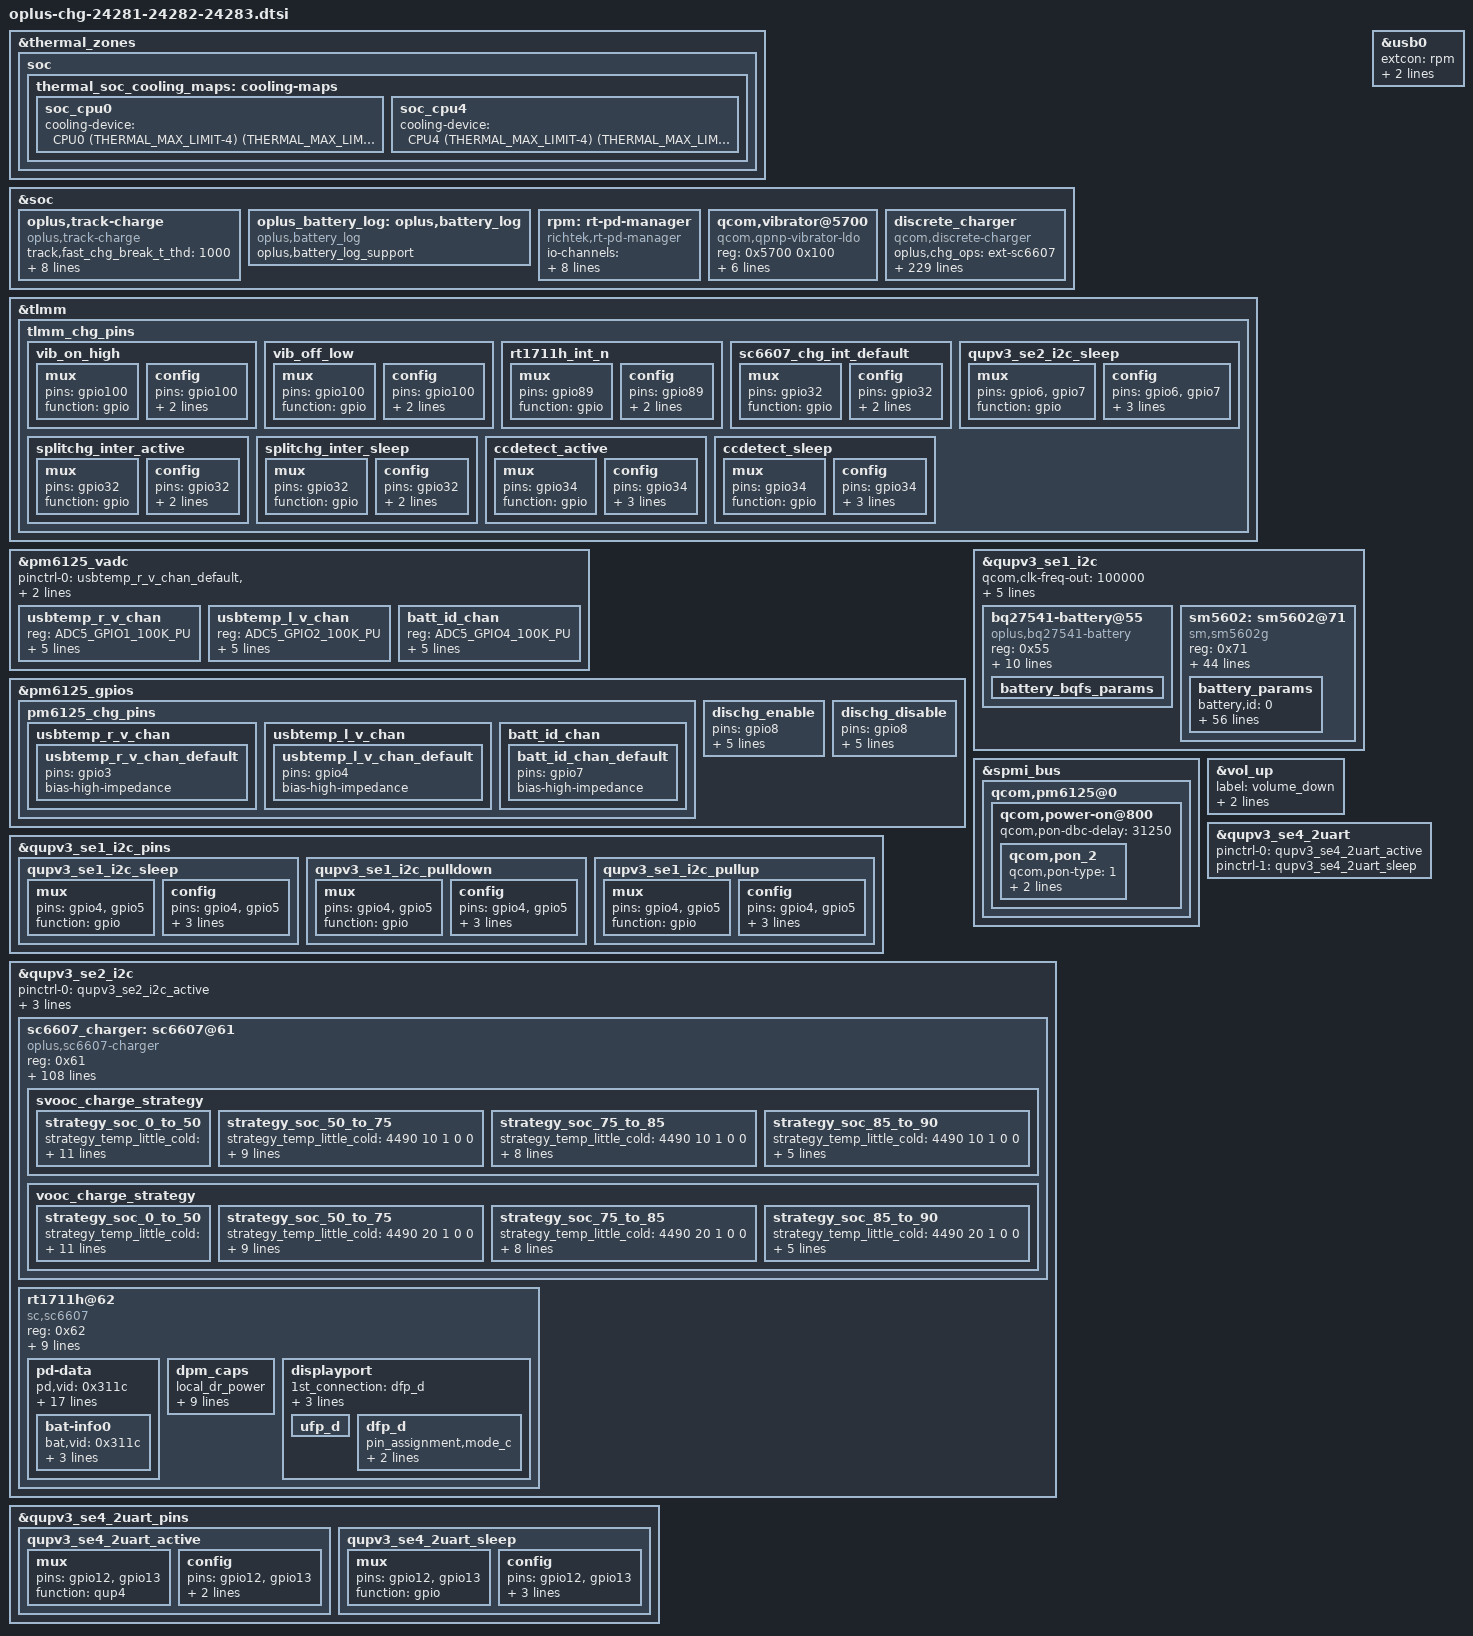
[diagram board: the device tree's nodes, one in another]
#include <dt-bindings/iio/qti_power_supply_iio.h>

&thermal_zones {
	soc {
		thermal_soc_cooling_maps: cooling-maps {
			soc_cpu0 {
				cooling-device =
					<&CPU0 (THERMAL_MAX_LIMIT-4)
						(THERMAL_MAX_LIMIT-4)>;
			};

			soc_cpu4 {
				cooling-device =
					<&CPU4 (THERMAL_MAX_LIMIT-4)
						(THERMAL_MAX_LIMIT-4)>;
			};

			/*soc_cpu6 {
				cooling-device = <&cpu6_isolate 1 1>;
			};

			soc_cpu7 {
				cooling-device = <&cpu7_isolate 1 1>;
			};*/
		};
	};
};

&soc {
	oplus,track-charge {
		compatible = "oplus,track-charge";
		track,fast_chg_break_t_thd = <1000>;
		track,general_chg_break_t_thd = <200>;
		track,voocphy_type = <2>;
		track,wired_max_power = <45000>;
		track,wired_fast_chg_scheme = <4>;
		track,gauge_status_ctrl;
		track,nominal_qmax1 = <5166>;
		track,nominal_fcc1 = <4700>;
		track,external_gauge_num = <1>;
	};

	oplus_battery_log: oplus,battery_log {
		compatible = "oplus,battery_log";
		oplus,battery_log_support;
	};
};

&tlmm {
	tlmm_chg_pins: tlmm_chg_pins {
		vib_on_high: vib_on_high {
			mux {
				pins = "gpio100";
				function = "gpio";
			};

			config {
				pins = "gpio100";
				drive-strength = <2>;
				output-high;
			};
		};
		vib_off_low: vib_off_low {
			mux {
				pins = "gpio100";
				function = "gpio";
			};

			config {
				pins = "gpio100";
				drive-strength = <2>;
				output-low;
			};
		};

		rt1711h_int_n: rt1711h_int_n {
			mux {
				pins = "gpio89";
				function = "gpio";
			};

			config {
				pins = "gpio89";
				drive-strength = <2>;
				bias-disable;
			};
		};

		sc6607_chg_int_default: sc6607_chg_int_default {
			mux {
				pins = "gpio32";
				function = "gpio";
			};

			config {
				pins = "gpio32";
				drive-strength = <2>;
				bias-disable;
			};
		};

		qupv3_se2_i2c_sleep: qupv3_se2_i2c_sleep {
				mux {
					pins = "gpio6", "gpio7";
					function = "gpio";
				};

				config {
					pins = "gpio6", "gpio7";
					drive-strength = <2>;
					bias-no-pull;
					output-high;
				};
		};

		/*split_chg*/
		splitchg_inter_active: splitchg_inter_active {
			mux {
				pins = "gpio32";
				function = "gpio";
			};
			config {
				pins = "gpio32";
				drive-strength = <2>;
				bias-pull-up;
			};
		};

		splitchg_inter_sleep: splitchg_inter_sleep {
			mux {
				pins = "gpio32";
				function = "gpio";
			};
			config {
				pins = "gpio32";
				drive-strength = <2>;
				bias-pull-up;
			};
		};

		ccdetect_active: ccdetect_active {
			mux {
				pins = "gpio34";
				function = "gpio";
			};
			config {
				pins = "gpio34";
				drive-strength = <2>;
				input-enable;
				//bias-pull-up; /*PULL UP*/
				bias-disable;
			};
		};

		ccdetect_sleep: ccdetect_sleep {
			mux {
				pins = "gpio34";
				function = "gpio";
			};
			config {
				pins = "gpio34";
				drive-strength = <2>;
				//output-low;
				//bias-pull-down; /*PULL DOWN*/
				input-enable;
				bias-disable;
			};
		};
	};
};

&pm6125_vadc {
	pinctrl-0 = <&usbtemp_r_v_chan_default &usbtemp_l_v_chan_default &batt_id_chan_default>;

	usbtemp_r_v_chan {
		reg = <ADC5_GPIO1_100K_PU>;
		label = "usbtemp_r_v_chan";
		qcom,ratiometric;
		qcom,hw-settle-time = <200>;
		qcom,pre-scaling = <1 1>;
		qcom,scale-fn-type = <ADC_SCALE_HW_CALIB_DEFAULT>;
	};

	usbtemp_l_v_chan {
		reg = <ADC5_GPIO2_100K_PU>;
		label = "usbtemp_l_v_chan";
		qcom,ratiometric;
		qcom,hw-settle-time = <200>;
		qcom,pre-scaling = <1 1>;
		qcom,scale-fn-type = <ADC_SCALE_HW_CALIB_DEFAULT>;
	};

	batt_id_chan {
		reg = <ADC5_GPIO4_100K_PU>;
		label = "batt_id_chan";
		qcom,ratiometric;
		qcom,hw-settle-time = <200>;
		qcom,pre-scaling = <1 1>;
		qcom,scale-fn-type = <ADC_SCALE_HW_CALIB_DEFAULT>;
	};
};

&pm6125_gpios {
	pm6125_chg_pins: pm6125_chg_pins {
			usbtemp_r_v_chan {
				usbtemp_r_v_chan_default: usbtemp_r_v_chan_default {
					pins = "gpio3";
					bias-high-impedance;
				};
			};

			usbtemp_l_v_chan {
				usbtemp_l_v_chan_default: usbtemp_l_v_chan_default {
					pins = "gpio4";
					bias-high-impedance;
				};
			};

			batt_id_chan {
				batt_id_chan_default: batt_id_chan_default {
					pins = "gpio7";
					bias-high-impedance;
				};
			};
	};
	dischg_enable: dischg_enable {
		pins = "gpio8";
		function = "normal";
		power-source = <0>;
		output-high;
		input-disable;
		qcom,drive-strength = <2>;
	};

	dischg_disable: dischg_disable {
		pins = "gpio8";
		function = "normal";
		power-source = <0>;
		output-low;
		input-disable;
		qcom,drive-strength = <2>;
	};
};

&qupv3_se1_i2c_pins {
	qupv3_se1_i2c_sleep: qupv3_se1_i2c_sleep {
		mux {
			pins = "gpio4", "gpio5";
			function = "gpio";
		};

		config {
			pins = "gpio4", "gpio5";
			drive-strength = <2>;
			bias-no-pull;
			output-high;
		};
	};
	qupv3_se1_i2c_pulldown: qupv3_se1_i2c_pulldown {
		mux {
			pins = "gpio4", "gpio5";
			function = "gpio";
		};

		config {
			pins = "gpio4", "gpio5";
			drive-strength = <2>;
			bias-pull-down;
			output-low;
		};
	};

	qupv3_se1_i2c_pullup: qupv3_se1_i2c_pullup {
		mux {
			pins = "gpio4", "gpio5";
			function = "gpio";
		};

		config {
			pins = "gpio4", "gpio5";
			drive-strength = <2>;
			bias-pull-up;
			input-enable;
		};
	};
};

&qupv3_se1_i2c {
	status = "okay";
	qcom,clk-freq-out = <100000>;
	pinctrl-names = "default", "sleep", "pulldown", "pullup";
	pinctrl-0 = <&qupv3_se1_i2c_active>;
	pinctrl-1 = <&qupv3_se1_i2c_sleep>;
	pinctrl-2 = <&qupv3_se1_i2c_pulldown>;
	pinctrl-3 = <&qupv3_se1_i2c_pullup>;
	oplus,i2c-auto-suspend-delay-ms = <3000>;
	bq27541-battery@55 {
		status = "okay";
		compatible = "oplus,bq27541-battery";
		reg = <0x55>;
		io-channels = <&pm6125_vadc ADC5_GPIO4_100K_PU>;
		io-channel-names = "batt_id_chan";
		dep-supply = <&pm6125_vadc>;
		oplus,gauge_abnormal_vbatt_max = <4800>;
		oplus,gauge_abnormal_vbatt_min = <2000>;
		oplus,cp_abnormal_fcc_max = <6600>;
		oplus,cp_abnormal_fcc_min = <3000>;
		oplus,cp_abnormal_soh_max = <100>;
		oplus,cp_abnormal_soh_min = <70>;
		oplus,cp_abnormal_qmax_max = <6600>;
		oplus,cp_abnormal_qmax_min = <4000>;
		battery_bqfs_params {
			#include "oplus-bqfs-24281.dtsi"
		};
	};

	sm5602:sm5602@71 {
		compatible = "sm,sm5602g";
		reg = <0x71>;

		sm,en_temp_ex;
		//sm,en_temp_in;
		//sm,en_temp_3rd;
		//sm,en_batt_det;
		sm,iocv_man_mode;
		sm,misc = <0x0800 0x0400>; //ex : 0x0800(Disabled DIS_HARD_RESET)
		sm,aging_ctrl = <0x0121>;
		sm,cycle_cfg = <0x7000>;
		sm,rsns = <5>;
		sm,battery_table_num = <0>;
		sm,param_version = <1>;
		sm,rpara = <0x0>;
		sm,curr_voffset = <0>;
		sm,curr_vslope = <0x8080>;

		//ENABLE_IOCV_ADJ
		sm,enable_iocv_adj;
		sm,iocv_max_adj_level = <0x1F33>;
		sm,iocv_min_adj_level = <0x1d70>;
		sm,ioci_max_adj_level = <0x1000>;
		sm,ioci_min_adj_level = <0xCC>;
		sm,iocv_i_slope = <100>;
		sm,iocv_i_offset = <0>;

		//ENABLE_INSPECTION_TABLE
		sm,enable_inspection_table;

		//ENABLE_TEMBASE_ZDSCON
		sm,enable_tembase_zdscon;
		sm,zdscon_act_temp_gap = <15>;
		sm,t_gap_denom = <5>;
		sm,hminman_t_value_fast = <125>;
		sm,i_gap_denom = <1000>;
		sm,hminman_i_value_fast = <150>;

		//ENABLE_TEMP_AVG
		sm,enable_temp_avg;
		sm,change_temp_time_limit = <1>;

		//ENABLE_NTC_COMPENSATION
		//sm,enable_ntc_compensation;
		sm,rtrace = <4700>;
		sm,overheat_th_deg = <50>;
		sm,cold_th_deg = <0>;

		//ENABLE_LTIM_ACT
		sm,enable_ltim_act;
		sm,ltim_act_temp_gap = <24>;
		sm,ltim_i_limit = <1500>;
		sm,ltim_factor = <42>;
		sm,ltim_denom = <130>;
		sm,ltim_min = <0xA>;

		//ENABLE_HCIC_ACT
		sm,enable_hcic_act;
		sm,hcic_min = <4000>;
		sm,hcic_factor = <2>;
		sm,hcic_denom = <200>;

		//ENABLE_HCRSM_MODE
		//sm,enable_hcrsm_mode;
		sm,hcrsm_volt = <4450>;
		sm,hcrsm_curr = <1750>;
		sm,hcrsm_min_soc = <900>;

		//CHECK_ABNORMAL_TABLE
		sm,enable_check_abnormal_table;

		battery_params {
			//1st NVT Battery( pack, liwon µçÐ¾
		    	battery,id = <0>;
			battery0,param_version = <1>;
		    	battery0,max_voltage_uv = <4500000>;
		        battery0,battery_type = <4500 0x0 0x2C20>;
		    	battery0,battery_table0 = <0x1400 0x1B33 0x1C3B 0x1D08 0x1D78 0x1D92 0x1DA1 0x1DEA 0x1E17 0x1E66 0x1E86 0x1EAF 0x1EE3 0x1F4F 0x1FDA 0x203F 0x20AC 0x2123 0x21A2 0x2230 0x2286 0x2320 0x2373 0x2666>;
		    	battery0,battery_table1 = <0x0 0x66 0x196 0x322 0x4AD 0x7C5 0xB60 0x1087 0x15AE 0x1D69 0x2290 0x27B7 0x2CDE 0x3498 0x39BF 0x3EE6 0x440E 0x4935 0x4E5C 0x5616 0x59B1 0x60E8 0x6400 0x64E6>;
			battery0,battery_table2 = <0x1A2B 0x1215 0x1011 0x0D0E 0x0C0C 0x0B0B 0x0B0B 0x0A0A>;
			battery0,alpha = <0x00CC>;
			battery0,beta = <0x0025>;
			battery0,rs = <0x8052>;
			battery0,rs_value = <0x0050 0x010A 0x3800 0x0048>;
			battery0,vit_period = <0x315A>;
			battery0,volt_cal = <0x8000>;
			battery0,mix_value = <0x0003>;
			battery0,curr_offset = <0x0000>;
			battery0,curr_slope = <0x8080>;
			battery0,topoff_soc = <7 450 150>;
			battery0,temp_std = <25>;
			battery0,temp_offset = <0 11 1 0 8 (-1)>;
			battery0,temp_cal = <0 6 1 11 (-1) 0 6 1 9 1>;
			battery0,ext_temp_cal = <0 2 1 2 1 1 2 3 2 3>;
			battery0,static_scale_soc = <0 991 1000 (-50) 50 1>;
			battery0,tem_poff = <3400 100>;
			battery0,thermal_table = <0x6177 0x60E6 0x604E 0x5FAF 0x5F06 0x5E56 0x5DA3 0x5CEC 0x5C27 0x5B5A
					 0x5A88 0x59AD 0x58C6 0x57D8 0x56E5 0x55E8 0x54E5 0x53CF 0x52B5 0x519B
					 0x506E 0x4F35 0x4E07 0x4CC0 0x4B76 0x4A25 0x48BD 0x475D 0x45F5 0x4477
					 0x4304 0x4175 0x3FDE 0x3E4A 0x3CA2 0x3AF6 0x3945 0x378A 0x35CB 0x33FC
					 0x322B 0x3059 0x2E82 0x2CA0 0x2AC6 0x28C6 0x26E0 0x24EA 0x22E8 0x20EF
					 0x1EE7 0x1CEE 0x1AE8 0x18D0 0x16D6 0x14CE 0x12F3 0x10E4 0x0ED6 0x0CC4
					 0x0ABC 0x08BC 0x06A8 0x04AD 0x02A1 0x009E 0xF669 0xF471 0xF278 0xF081
					 0xEE7B 0xEC8C 0xEAA1 0xE8BE 0xE6E1 0xE505 0xE332 0xE162 0xDF9B 0xDDD9
					 0xDC1F 0xDA67 0xD8B4 0xD70B 0xD565 0xD3C7 0xD232 0xD0A1 0xCF18 0xCD94
					 0xCC18 0xCAA5 0xC936 0xC7D3 0xC670 0xC519 0xC3C6 0xC27A 0xC136 0xBFF7
					 0xBEC1 0xBD92 0xBC6E 0xBB4D 0xBA36 0xB922 0xB816 0xB712 0xB611 0xB517
					 0xB422 0xB334 0xB249 0xB164 0xB085 0xAFAD 0xAED8 0xAE0A 0xAD3E 0xAC78
					 0xABB7 0xAAFD 0xAA48 0xA997 0xA8E8 0xA841>;  //NTC value(DEC) table -40~85 20K PU,20K PD/10K NTC
			//2nd SWD Battery(pack, ATL µçÐ¾
	    		//battery,id = <1>;
			battery1,param_version = <1>;
		    	battery1,max_voltage_uv = <4500000>;
		        battery1,battery_type = <4500 0x0 0x2CA8>;
		    	battery1,battery_table0 = <0x1400 0x1B32 0x1C51 0x1D12 0x1D78 0x1D93 0x1DB5 0x1DF5 0x1E20 0x1E68 0x1E86 0x1EB0 0x1EE5 0x1F55 0x1FDD 0x203F 0x20AB 0x2122 0x21A1 0x222B 0x2281 0x231D 0x2370 0x2666>;
		    	battery1,battery_table1 = <0x0 0x66 0x1BC 0x343 0x4CA 0x8DD 0xC6E 0x1185 0x169C 0x1E3F 0x2357 0x286E 0x2D85 0x3529 0x3A40 0x3F57 0x446F 0x4986 0x4E9D 0x5640 0x59D1 0x60F1 0x6400 0x64E6>;
			battery1,battery_table2 = <0x1B2D 0x1517 0x1213 0x0F10 0x0E0F 0x0D0E 0x0C0D 0x0C0C>;
			battery1,alpha = <0x00CC>;
			battery1,beta = <0x0025>;
			battery1,rs = <0x8052>;
			battery1,rs_value = <0x0050 0x010A 0x3800 0x0048>;
			battery1,vit_period = <0x315A>;
			battery1,volt_cal = <0x8000>;
			battery1,mix_value = <0x0003>;
			battery1,curr_offset = <0x0000>;
			battery1,curr_slope = <0x8080>;
			battery1,topoff_soc = <7 450 150>;
			battery1,temp_std = <25>;
			battery1,temp_offset = <0 11 1 0 8 (-1)>;
			battery1,temp_cal = <0 6 1 11 (-1) 0 6 1 9 1>;
			battery1,ext_temp_cal = <0 2 1 2 1 1 2 3 2 3>;
			battery1,static_scale_soc = <0 991 1000 (-50) 50 1>;
			battery1,tem_poff = <3400 100>;
			battery1,thermal_table = <0x506E 0x4F35 0x4E07 0x4CC0 0x4B76 0x4A25 0x48BD 0x475D 0x45F5 0x4477
						0x4304 0x4175 0x3FDE 0x3E4A 0x3CA2 0x3AF6 0x3945 0x378A 0x35CB 0x33FC
						0x322B 0x3059 0x2E82 0x2CA0 0x2AC6 0x28C6 0x26E0 0x24EA 0x22E8 0x20EF
						0x1EE7 0x1CEE 0x1AE8 0x18D0 0x16D6 0x14CE 0x12F3 0x10E4 0x0ED6 0x0CC4
						0x0ABC 0x08BC 0x06A8 0x04AD 0x02A1 0x009E 0xF669 0xF471 0xF278 0xF081
						0xEE7B 0xEC8C 0xEAA1 0xE8BE 0xE6E1 0xE505 0xE332 0xE162 0xDF9B 0xDDD9
						0xDC1F 0xDA67 0xD8B4 0xD70B 0xD565 0xD3C7 0xD232 0xD0A1 0xCF18 0xCD94
						0xCC18 0xCAA5 0xC936 0xC7D3 0xC670 0xC519 0xC3C6 0xC27A 0xC136 0xBFF7
						0xBEC1 0xBD92 0xBC6E 0xBB4D 0xBA36 0xB922 0xB816 0xB712 0xB611 0xB517
						0xB422 0xB334 0xB249 0xB164 0xB085 0xAFAD 0xAED8 0xAE0A 0xAD3E 0xAC78
						0xABB7>;  //NTC value(DEC) table -20~80 20K PU,20K PD/10K NTC
		};
	};
};


&soc {
	rpm: rt-pd-manager {
		compatible = "richtek,rt-pd-manager";
		#io-channel-cells = <1>;
		io-channels = <&discrete_charger PSY_IIO_PD_ACTIVE>,
			      <&discrete_charger PSY_IIO_PD_USB_SUSPEND_SUPPORTED>,
			      <&discrete_charger PSY_IIO_PD_IN_HARD_RESET>,
			      <&discrete_charger PSY_IIO_PD_CURRENT_MAX>,
			      <&discrete_charger PSY_IIO_PD_VOLTAGE_MIN>,
			      <&discrete_charger PSY_IIO_PD_VOLTAGE_MAX>,
			      <&discrete_charger PSY_IIO_USB_REAL_TYPE>,
			      <&discrete_charger PSY_IIO_PD_SDP>;
		io-channel-names = "pd_active",
				   "pd_usb_suspend_supported",
				   "pd_in_hard_reset",
				   "pd_current_max",
				   "pd_voltage_min",
				   "pd_voltage_max",
				   "real_type",
				   "pd_sdp";
	};
};
/* load vibrator for rm pmic */
&soc {
	qcom,vibrator@5700 {
			compatible = "qcom,qpnp-vibrator-ldo";
			reg = <0x5700 0x100>;
			qcom,vib-ldo-volt-uv = <3000000>;
			qcom,disable-overdrive;
			qcom,vib-type = <1>;	/* 0:ldo 1:gpio */
			status = "okay";

			qcom,vibrator_switch-gpio = <&tlmm 100 0x00>;
			pinctrl-names = "vib_on_high", "vib_off_low";
			pinctrl-0 = <&vib_on_high>;
			pinctrl-1 = <&vib_off_low >;
	};
};

&spmi_bus {
	qcom,pm6125@0 {
		qcom,power-on@800 {
			qcom,pon-dbc-delay = <31250>;
		};
	};
};

&vol_up {
	label = "volume_down";
	linux,code = <KEY_VOLUMEDOWN>;
	debounce-interval = <32>;
};

&qupv3_se2_i2c {
	status = "okay";
	pinctrl-0 = <&qupv3_se2_i2c_active>;
	pinctrl-1 = <&qupv3_se2_i2c_sleep>;
	qcom,clk-freq-out = <400000>;
	oplus,i2c-auto-suspend-delay-ms = <3000>;
	sc6607_charger:sc6607@61 {
		status = "okay";
		compatible = "oplus,sc6607-charger";
		reg = <0x61>; /*The device operates as a slave device with address 75H*/

		qcom,chg_irq_gpio = <&tlmm 32 0x00>;
		dpdm-supply = <&qusb_phy0>;
		pinctrl-names = "default",
				"splitchg_inter_active",
				"splitchg_inter_sleep";

		pinctrl-0 = <&sc6607_chg_int_default>;
		pinctrl-1 = <&splitchg_inter_active>;
		pinctrl-2 = <&splitchg_inter_sleep>;

		sc,vsys-limit = <3400>;
		sc,vbat = <4450>;
		sc,charge-curr = <2000>;
		sc,iindpm-disable = <0>;
		sc,input-curr-limit = <500>;
		sc,ico-enable = <0>;
		sc,precharge-volt = <0>;      /* 0:2700mv , 1:3000mv */
		sc,precharge-curr = <500>;
		sc,term-en = <1>;
		sc,term-curr = <100>;     /* ma */
		sc,rechg-dis = <1>;
		sc,boost-voltage = <5000>;
		sc,boost-max-current = <1500>;
		sc,support-tsbat-1000k;
		sc,conv-ocp-dis = <0>;
		sc,tsbat-jeita-dis = <1>;
		sc,vpmid-ovp-otg-dis = <0>;
		sc,vbat-ovp-buck-dis = <0>;
		sc,ibat-ocp = <1>;    /* 0:10A , 1:16A */
		ovp_reg = <0x36>; /* 4850mv */
		ocp_reg = <0xf>;    /* 4.75A*/
		pmid2out_ovp_thr = <0x07>; /* 600mV */
		sc,charge-detect-enable;
		sc,disable-qc;
		sc,cc_pull_up_idrive = <0x09>;
		sc,cc_pull_down_idrive = <0x43>;
		sc,continuous_time = <0x4E>;
		sc,bmc_width = <0x86 0x3d 0x3b 0x10>;
		qcom,copycat_vooc_support;
		oplus,copycat_identify_algorithm = <2>;
		oplus,copycat-vooc-count = <4>;

		/*
		 * Charger name
		 * Main charger: primary_chg
		 * Slave charger: secondary_chg
		 */
		charger_name = "primary_chg";


		qcom,voocphy_current_default = <41>;/*4100mA*/

		qcom,svooc_cool_down_current_limit = <82 20 20 24 30 34 40 44 50 54 82>;
		qcom,vooc_cool_down_current_limit = <30 20 20 24 30>;
		qcom,abnormal_adapter_current = <60 60 40 40>;
		oplus,workaround_for_100w;
		qcom,vooc_little_cold_full_voltage = <4490>;
		qcom,vooc_cool_full_voltage = <4500>;
		qcom,vooc_warm_full_voltage = <4130>;
		qcom,vooc_1time_full_voltage = <4560>;
		qcom,vooc_ntime_full_voltage = <4550>;
		qcom,low_curr_full_t1 = <120>;
		qcom,low_curr_full_t2 = <350>;
		qcom,low_curr_full_t3 = <430>;
		qcom,range1_low_curr_full = <1350 4550
					     1300 4545
					     1200 4530
					     1100 4520
					     950 4510>;
		qcom,range2_low_curr_full = <1950 4550
					     1900 4545
					     1800 4530
					     1700 4520
					     1550 4510>;

		qcom,vooc_multistep_initial_batt_temp = <1000>;
		qcom,vooc_little_cool_temp = <200>;
		qcom,vooc_cool_temp = <120>;
		qcom,vooc_little_cold_temp = <50>;
		qcom,vooc_normal_low_temp = <350>;
		qcom,vooc_strategy_normal_current = <100>;
		qcom,vooc_normal_to_little_cool_current = <100>;
		qcom,vooc_batt_over_high_temp = <510>;
		qcom,vooc-low-temp = <0>;
		qcom,vooc-high-temp = <500>;
		qcom,vooc-low-soc = <0>;
		qcom,vooc-high-soc = <90>;
		qcom,vooc-normal-high-temp = <440>;
		qcom,vooc-warm-allow-vol = <4000>;
		qcom,vooc-warm-allow-soc = <50>;
		qcom,impedance_calculation_newmethod;
		qcom,svooc_circuit_r_l = <0x18>;
		qcom,svooc_circuit_r_h = <0x2>;/* 65 mR */

		qcom,vooc_strategy1_batt_high_temp0 = <385>;
		qcom,vooc_strategy1_batt_high_temp1 = <395>;
		qcom,vooc_strategy1_batt_high_temp2 = <420>;
		qcom,vooc_strategy1_batt_low_temp2 = <410>;
		qcom,vooc_strategy1_batt_low_temp1 = <385>;
		qcom,vooc_strategy1_batt_low_temp0 = <375>;

		qcom,vooc_strategy1_high_current0 = <82>;
		qcom,vooc_strategy1_high_current1 = <60>;
		qcom,vooc_strategy1_high_current2 = <40>;
		qcom,vooc_strategy1_low_current2 = <60>;
		qcom,vooc_strategy1_low_current1 = <60>;
		qcom,vooc_strategy1_low_current0 = <82>;

		qcom,vooc_strategy1_high_current0_vooc = <30>;
		qcom,vooc_strategy1_high_current1_vooc = <30>;
		qcom,vooc_strategy1_high_current2_vooc = <30>;
		qcom,vooc_strategy1_low_current2_vooc = <30>;
		qcom,vooc_strategy1_low_current1_vooc = <30>;
		qcom,vooc_strategy1_low_current0_vooc = <30>;

		qcom,voocphy_ibat_over_current = <8500>;
		qcom,voocphy_cp_max_ibus = <4750>;
		qcom,voocphy_svooc_cp_max_ibus = <4750>;
		qcom,voocphy_vooc_cp_max_ibus = <3500>;
		qcom,batt_pwd_curr_thd1 = <4300>;
		qcom,batt_pwd_vol_thd1 = <4514>;

		qcom,voocphy_freq_mincore = <1017600>;
		qcom,voocphy_freq_midcore = <1804800>;
		qcom,voocphy_freq_maxcore = <1804800>;
		qcom,voocphy_current_change_timeout = <100>;
		oplus,sc6607_ntc_surport_1000k = <
			(-40) 4251000 (-39) 3962000 (-38) 3695000 (-37) 3447000 (-36) 3218000 (-35) 3005000
			(-34) 2807000 (-33) 2624000 (-32) 2454000 (-31) 2296000 (-30) 2149000 (-29) 2012000
			(-28) 1885000 (-27) 1767000 (-26) 1656000 (-25) 1554000 (-24) 1458000 (-23) 1369000
			(-22) 1286000 (-21) 1208000 (-20) 1135000 (-19) 1068000 (-18) 1004000 (-17) 945000
			(-16) 889600 (-15) 837800 (-14) 789300 (-13) 743900 (-12) 701300 (-11) 661500
			(-10) 624100 (-9) 589000 (-8) 556200 (-7) 525300 (-6) 496300 (-5) 469100
			(-4) 443500 (-3) 419500 (-2) 396900 (-1) 375600 0 355600 1 336800
			2 319100 3 302400 4 286700 5 271800 6 257800 7 244700
			8 232200 9 220500 10 209400 11 198900 12 189000 13 179700
			14 170900 15 162500 16 154600 17 147200 18 140100 19 133400
			20 127000 21 121000 22 115400 23 110000 24 104800 25 100000
			26 95400 27 91040 28 86900 29 82970 30 79230 31 75690
			32 72320 33 69120 34 66070 35 63180 36 60420 37 57810
			38 55310 39 52940 40 50680 41 48530 42 46490 43 44530
			44 42670 45 40900 46 39210 47 37600 48 36060 49 34600
			50 33190 51 31860 52 30580 53 29360 54 28200 55 27090
			56 26030 57 25010 58 24040 59 23110 60 22220 61 21370
			62 20560 63 19780 64 19040 65 18320 66 17640 67 16990
			68 16360 69 15760 70 15180 71 14630 72 14100 73 13600
			74 13110 75 12640 76 12190 77 11760 78 11350 79 10960
			80 10580 81 10210 82 9859 83 9522 84 9198 85 8887
			86 8587 87 8299 88 8022 89 7756 90 7500 91 7254
			92 7016 93 6788 94 6568 95 6357 96 6153 97 5957
			98 5768 99 5586 100 5410 101 5241 102 5078 103 4921
			104 4769 105 4623 106 4482 107 4346 108 4215 109 4088
			110 3966 111 3848 112 3734 113 3624 114 3518 115 3415
			116 3316 117 3220 118 3128 119 3038 120 2952 121 2868
			122 2787 123 2709 124 2634 125 2561>;

		svooc_batt_sys_curve = <0 1 0 1 0 0 1	// 4100mA
					0 0 0 0 0 0 1	// 3414mV
					0 0 1 0 1 0 0	// 2000mA
					1 1 1 1 1 1 0	// 4664mV
					0 0 0 1 0 1 0	// 1000mA
					1 1 1 1 1 1 0>;	// 4664mV

		vooc_batt_sys_curve =  <0 0 1 1 1 1 0	// 3000mA
					0 0 0 0 0 0 1	// 3414mV
					0 0 1 0 1 0 0	// 2000mA
					1 1 1 1 1 1 0	// 4664mV
					0 0 0 1 0 1 0	// 1000mA
					1 1 1 1 1 1 0>;	// 4664mV

	    svooc_charge_strategy {
			strategy_soc_0_to_50 {
				strategy_temp_little_cold =	<4150 19 0 0 0
								 4150 15 0 0 0
								 4480 13 0 0 0
								 4490 10 1 0 0>;
				strategy_temp_cool =		<4150 28 0 0 0
								 4150 25 0 0 0
								 4150 20 0 0 0
								 4490 19 0 0 0
								 4490 15 0 0 0
								 4500 10 1 0 0>;
				strategy_temp_little_cool = 	<4150 41 0 0 0
								 4150 40 0 0 0
								 4150 35 0 0 0
								 4510 33 0 0 0
								 4510 30 0 0 0
								 4510 25 0 0 0
								 4540 22 0 0 0
								 4540 20 0 0 0
								 4540 15 0 0 0
								 4550 10 1 0 0>;
				strategy_temp_normal_low = 	<4230 41 0 0 0
								 4230 40 0 0 0
								 4230 35 0 0 0
								 4510 33 0 0 0
								 4510 30 0 0 0
								 4510 25 0 0 0
								 4540 22 0 0 0
								 4540 20 0 0 0
								 4540 15 0 0 0
								 4550 10 1 0 0>;
				strategy_temp_normal_high =	<4230 41 0 0 0
								 4230 40 0 0 0
								 4230 35 0 0 0
								 4510 33 0 0 0
								 4510 30 0 0 0
								 4510 25 0 0 0
								 4540 22 0 0 0
								 4540 20 0 0 0
								 4540 15 0 0 0
								 4550 10 1 0 0>;
				strategy_temp_warm =		<4120 15 0 0 0
								 4130 10 1 0 0>;
			};

			strategy_soc_50_to_75 {
				strategy_temp_little_cold =	<4490 10 1 0 0>;
				strategy_temp_cool =		<4490 15 0 0 0
								 4500 10 1 0 0>;
				strategy_temp_little_cool = 	<4540 20 0 0 0
								 4540 15 0 0 0
								 4550 10 1 0 0>;
				strategy_temp_normal_low = 	<4510 25 0 0 0
								 4540 22 0 0 0
								 4540 20 0 0 0
								 4540 15 0 0 0
								 4550 10 1 0 0>;
				strategy_temp_normal_high =	<4510 25 0 0 0
								 4540 22 0 0 0
								 4540 20 0 0 0
								 4540 15 0 0 0
								 4550 10 1 0 0>;
				strategy_temp_warm =		<4130 10 1 0 0>;//no fastcharge
			};

			strategy_soc_75_to_85 {
				strategy_temp_little_cold = 	<4490 10 1 0 0>;
				strategy_temp_cool =		<4500 10 1 0 0>;
				strategy_temp_little_cool =	<4540 15 0 0 0
								 4550 10 1 0 0>;
				strategy_temp_normal_low =	<4540 15 0 0 0
								 4550 10 1 0 0>;
				strategy_temp_normal_high =	<4540 15 0 0 0
								 4550 10 1 0 0>;
				strategy_temp_warm =		<4130 10 1 0 0>;//no fastcharge
			};

			strategy_soc_85_to_90 {
				strategy_temp_little_cold = 	<4490 10 1 0 0>;
				strategy_temp_cool =		<4500 10 1 0 0>;
				strategy_temp_little_cool =	<4550 10 1 0 0>;
				strategy_temp_normal_low =	<4550 10 1 0 0>;
				strategy_temp_normal_high =	<4550 10 1 0 0>;
				strategy_temp_warm =		<4130 10 1 0 0>;//no fastcharge
			};
		};

		vooc_charge_strategy {
			strategy_soc_0_to_50 {
				strategy_temp_little_cold =	<4150 30 0 0 0
								 4480 26 0 0 0
								 4490 20 1 0 0>;
				strategy_temp_cool =		<4490 30 0 0 0
								 4500 20 1 0 0>;
				strategy_temp_little_cool =	<4540 30 0 0 0
								 4550 20 1 0 0>;
				strategy_temp_normal_low =	<4540 30 0 0 0
								 4550 20 1 0 0>;
				strategy_temp_normal_high =	<4540 30 0 0 0
								 4550 20 1 0 0>;
				strategy_temp_warm =		<4120 30 0 0 0
								 4130 20 1 0 0>;
			};

			strategy_soc_50_to_75 {
				strategy_temp_little_cold =	<4490 20 1 0 0>;
				strategy_temp_cool =		<4490 30 0 0 0
								 4500 20 1 0 0>;
				strategy_temp_little_cool =	<4540 30 0 0 0
								 4550 20 1 0 0>;
				strategy_temp_normal_low =	<4540 30 0 0 0
								 4550 20 1 0 0>;
				strategy_temp_normal_high =	<4540 30 0 0 0
								 4550 20 1 0 0>;
				strategy_temp_warm =		<4130 20 1 0 0>;
			};

			strategy_soc_75_to_85 {
				strategy_temp_little_cold =	<4490 20 1 0 0>;
				strategy_temp_cool =		<4500 20 1 0 0>;
				strategy_temp_little_cool =	<4540 30 0 0 0
								 4550 20 1 0 0>;
				strategy_temp_normal_low =	<4540 30 0 0 0
								 4550 20 1 0 0>;
				strategy_temp_normal_high =	<4540 30 0 0 0
								 4550 20 1 0 0>;
				strategy_temp_warm =		<4130 20 1 0 0>;
			};

			strategy_soc_85_to_90 {
				strategy_temp_little_cold =	<4490 20 1 0 0>;
				strategy_temp_cool =		<4500 20 1 0 0>;
				strategy_temp_little_cool =	<4550 20 1 0 0>;
				strategy_temp_normal_low =	<4550 20 1 0 0>;
				strategy_temp_normal_high =	<4550 20 1 0 0>;
				strategy_temp_warm =		<4130 20 1 0 0>;
			};
		};
	};


	rt1711h@62 {
		compatible = "sc,sc6607";
		reg = <0x62>;
		status = "okay";
		tcpc-dual,supported_modes = <0>; /* 0: dfp/ufp, */
						 /* 1: dfp, 2: ufp */
		rt-tcpc,name = "type_c_port0"; /* tcpc_device's name */
		rt-tcpc,role_def = <1>; /* 0: Unknown, 1: SNK, 2: SRC */
					/* 3: DRP, 4: Try.SRC, 5: Try.SNK */
		rt-tcpc,rp_level = <0>; /* 0: Default, 1: 1.5, 2: 3.0 */
		rt-tcpc,vconn_supply  = <1>;  /* 0: Never, 1: Always, */
					      /* 2: EMarkOnly, 3: StartOnly */
		/* rt-tcpc,disable_pe; */
		rt1711pd,intr_gpio = <&tlmm 89 0x0>;
		rt1711pd,intr_gpio_num = <89>;
		rt,disable_irq_reset;
		pinctrl-names = "default";
		pinctrl-0 = <&rt1711h_int_n>;
		pd-data {
			pd,vid = <0x311c>;
			pd,pid = <0x6600>;
			pd,source-cap-ext = /bits/ 8 <0x1c 0x31 0x00 0x66
						      0x00 0x00 0x00 0x00
						      0x00 0x00 0x00 0x00
						      0x00 0x00 0x00 0x00
						      0x00 0x00 0x00 0x00
						      0x00 0x00 0x01 0x05
						      0x00>;
			pd,sink-cap-ext = /bits/ 8 <0x1c 0x31 0x00 0x66
							   0x00 0x00 0x00 0x00
							   0x01 0x00 0x00 0x00
							   0x00 0x00 0x00 0x00
							   0x01 0x00 0x00 0x00
							   0x00 0x00 0x00 0x00>;
			pd,mfrs = "RichtekTCPC";

			/*
			 *	VSAFE5V = 0, MAX_POWER = 1, CUSTOM = 2,
			 *	MAX_POWER_LV = 0x21, MAX_POWER_LVIC = 0x31
			 *	MAX_POWER_HV = 0x41, MAX_POWER_HVIC = 0x51
			 */
			pd,charging_policy= <0>;

			/*
			 * Fixed 5V, 500 mA <0x00019032>
			 * Fixed 5V, 1A <0x00019064>
			 * Fixed 5V, 2A <0x000190c8>
			 * Fixed 5V, 3A <0x0001912c>
			 * Fixed 9V, 500 mA <0x0002d032>
			 * Fixed 9V, 1A <0x0002d064>
			 * Fixed 9V, 2A <0x0002d0c8>
			 * Fixed 9V, 3A <0x0002d12c>
			 * Variable 5-9V, 1A <0x8642d064>
			 * Variable 5-9V, 2A <0x8642d0c8>
			 * Variable 5-9V, 3A <0x8642d12c>
			 */
			pd,source-pdo-size = <1>;
			pd,source-pdo-data = <0x00019064>;
			pd,sink-pdo-size = <3>;
			pd,sink-pdo-data = <0x360190c8 0x0002d096 0xc0dc3252>;

			/*
			 * No DP, host + device
			 *	pd,id-vdo-size = <6>;
			 *	pd,id-vdo-data = <0xd14029cf 0x0 0x17110000
						  0x41800000 0x0 0x21800000>;
			 * With DP
			 *	pd,id-vdo-size = <6>;
			 *	pd,id-vdo-data = <0xd54029cf 0x0 0x17110000
						  0x41800000 0x0 0x21800000>;
			 */

			pd,id-vdo-size = <6>;
			pd,id-vdo-data = <0xd14029cf 0x0 0x17110000
					  0x41800000 0x0 0x21800000>;

			bat,nr = <1>;
			pd,country_nr = <0>;

			bat-info0 {
				bat,vid = <0x311c>;
				bat,pid = <0x6600>;
				bat,mfrs = "bat1";
				bat,design_cap = <17>;
			};

		};
		dpm_caps {
			local_dr_power;
			local_dr_data;
			//local_ext_power;
			local_usb_comm;
			//local_usb_suspend;
			//local_high_cap;
			//local_give_back;
			local_no_suspend;
			local_vconn_supply;

			//attempt_discover_cable_dfp;
			//attempt_enter_dp_mode;
			attempt_discover_cable;
			attempt_discover_id;
			attempt_discover_svid;

			/* 0: disable, 1: prefer_snk, 2: prefer_src */
			pr_check = <0>;
			//pr_reject_as_source;
			//pr_reject_as_sink;
			//pr_check_gp_source;
			//pr_check_gp_sink;

			/* 0: disable, 1: prefer_ufp, 2: prefer_dfp */
			dr_check = <0>;
			//dr_reject_as_dfp;
			//dr_reject_as_ufp;
		};
		displayport {
			/* connection type = "both", "ufp_d", "dfp_d" */
			1st_connection = "dfp_d";
			2nd_connection = "dfp_d";
			signal,dp_v13;
			//signal,dp_gen2;
			//usbr20_not_used;
			typec,receptacle;
			ufp_d {
				//pin_assignment,mode_a;
				//pin_assignment,mode_b;
				//pin_assignment,mode_c;
				//pin_assignment,mode_d;
				//pin_assignment,mode_e;
			};
			dfp_d {
				//pin_assignment,mode_a;
				//pin_assignment,mode_b;
				pin_assignment,mode_c;
				pin_assignment,mode_d;
				pin_assignment,mode_e;
				//pin_assignment,mode_f;
			};
		};
	};
};

&spmi_bus {
	qcom,pm6125@0 {
		qcom,power-on@800 {
			qcom,pon_2 {
				qcom,pon-type = <1>;
				qcom,pull-up = <1>;
				linux,code = <KEY_VOLUMEUP>;
			};
		};
	};
};

&soc {
	discrete_charger: discrete_charger {
		compatible = "qcom,discrete-charger";
		status = "okay";

		oplus,chg_ops = "ext-sc6607";
		#io-channel-cells = <1>;
		io-channels = <&pm6125_vadc ADC5_GPIO1_100K_PU>,
				      <&pm6125_vadc ADC5_GPIO2_100K_PU>;
		io-channel-names = "usbtemp_r_v_chan",
				"usbtemp_l_v_chan";
		dep-supply = <&pm6125_vadc>;
        //ntc switch gpio
        qcom,ntc-switch-gpio = <&tlmm 85 0x00>;

		pinctrl-names = "dischg_enable", "dischg_disable", "ccdetect_active", "ccdetect_sleep";

		pinctrl-0 = <&dischg_enable>;
		pinctrl-1 = <&dischg_disable>;
		pinctrl-2 = <&ccdetect_active>;
		pinctrl-3 = <&ccdetect_sleep>;

		qcom,support_abnormal_adapter;
		qcom,input_current_charger_ma = <2000>;
		qcom,pd_input_current_charger_ma = <1500>;
		qcom,qc_input_current_charger_ma = <2000>;
		qcom,input_current_usb_ma = <500>;
		qcom,input_current_cdp_ma = <1500>;
		qcom,input_current_camera_ma = <1200>;
		qcom,input_current_calling_ma = <1500>;

		qcom,led_warm_bat_decidegc = <350>;
		qcom,led_high_bat_decidegc = <370>;
		qcom,input_current_led_ma = <1200>;
		qcom,input_current_led_ma_high = <1200>;
		qcom,input_current_led_ma_warm = <1500>;
		qcom,input_current_led_ma_normal = <2000>;

		qcom,vooc_temp_bat_normal_decidegc = <350>;
		qcom,vooc_temp_bat_warm_decidegc = <370>;
		qcom,vooc_temp_bat_hot_decidegc = <440>;
		qcom,input_current_vooc_led_ma_high = <1200>;
		qcom,input_current_vooc_led_ma_warm = <1800>;
		qcom,input_current_vooc_led_ma_normal = <3600>;
		qcom,input_current_vooc_ma_normal = <3600>;

		qcom,input_current_vooc_ma_warm = <3200>;

		qcom,input_current_vooc_ma_high = <2200>;

		qcom,charger_current_vooc_ma_normal = <1800>;

		qcom,iterm_disabled = <0>;
		qcom,iterm_ma = <292>;
		qcom,recharge-mv = <100>;
		qcom,batt_capacity_mah = <5800>;/*typical capacity*/

		qcom,removed_bat_decidegc = <390>;  /*<-39C*/

		qcom,cold_bat_decidegc = <100>;  /*-10C~0C*/
		qcom,temp_cold_vfloat_mv = <4490>;
		qcom,temp_cold_fastchg_current_ma_high = <846>;
		qcom,temp_cold_fastchg_current_ma_low = <846>;
		qcom,temp_cold_fastchg_current_ma = <846>;
		qcom,pd_temp_cold_fastchg_current_ma_high = <846>;
		qcom,pd_temp_cold_fastchg_current_ma_low = <846>;
		qcom,qc_temp_cold_fastchg_current_ma_high = <800>;
		qcom,qc_temp_cold_fastchg_current_ma_low = <600>;

		qcom,little_cold_bat_decidegc = <0>;    /*0C~5C*/
		qcom,temp_little_cold_vfloat_mv = <4490>;
		qcom,temp_little_cold_fastchg_current_ma_high = <2200>;
		qcom,temp_little_cold_fastchg_current_ma_low = <2200>;
		qcom,temp_little_cold_fastchg_current_ma = <2200>;
		qcom,pd_temp_little_cold_fastchg_current_ma_high = <3300>;
		qcom,pd_temp_little_cold_fastchg_current_ma_low = <2538>;
		qcom,qc_temp_little_cold_fastchg_current_ma_high = <3000>;
		qcom,qc_temp_little_cold_fastchg_current_ma_low = <2000>;

		qcom,cool_bat_decidegc = <50>;  /*5C~12C*/
		qcom,temp_cool_vfloat_mv = <4490>;
		qcom,temp_cool_fastchg_current_ma_high = <2200>;
		qcom,temp_cool_fastchg_current_ma_low = <2200>;
		qcom,pd_temp_cool_fastchg_current_ma_high = <3300>;
		qcom,pd_temp_cool_fastchg_current_ma_low = <3300>;
		qcom,qc_temp_cool_fastchg_current_ma_high = <3000>;
		qcom,qc_temp_cool_fastchg_current_ma_low = <3000>;

		qcom,little_cool_bat_decidegc = <120>;  /*12C~16C*/
		qcom,temp_little_cool_vfloat_mv = <4490>;
		qcom,temp_little_cool_fastchg_current_ma = <2200>;
		qcom,pd_temp_little_cool_fastchg_current_ma = <3300>;
		qcom,qc_temp_little_cool_fastchg_current_ma = <3000>;

		qcom,normal_bat_decidegc = <160>;       /*16C~45C*/
		qcom,temp_normal_vfloat_mv = <4470>;
		qcom,temp_normal_fastchg_current_ma = <2200>;
		qcom,pd_temp_normal_fastchg_current_ma = <3300>;
		qcom,qc_temp_normal_fastchg_current_ma = <3000>;

		qcom,warm_bat_decidegc = <450>;         /*45C~53C*/ /*8pin Bat Vooc project need add 3 degree C*/
		qcom,temp_warm_vfloat_mv = <4130>;
		qcom,temp_warm_fastchg_current_ma = <2200>;
		qcom,pd_temp_warm_fastchg_current_ma = <3102>;
		qcom,qc_temp_warm_fastchg_current_ma = <2200>;
		qcom,temp_warm_fastchg_current_ma_led_on = <1000>;

		qcom,hot_bat_decidegc = <530>;

		qcom,non_standard_vfloat_mv = <3980>;
		qcom,non_standard_fastchg_current_ma = <500>;

		qcom,short_c_bat_cv_mv = <4330>;
		qcom,short_c_bat_vfloat_mv = <3800>;
		qcom,short_c_bat_fastchg_current_ma = <512>;

		qcom,cold_vfloat_sw_limit = <4440>;
		qcom,little_cold_vfloat_sw_limit = <4440>;
		qcom,cool_vfloat_sw_limit = <4440>;
		qcom,little_cool_vfloat_sw_limit = <4440>;
		qcom,normal_vfloat_sw_limit = <4420>;
		qcom,warm_vfloat_sw_limit = <4080>;
		qcom,non_standard_vfloat_sw_limit = <3930>;
		qcom,short_c_bat_vfloat_sw_limit = <3750>;

		qcom,max_chg_time_sec = <64800>;
		qcom,charger_hv_thr = <10000>;
		qcom,charger_recv_thr = <9800>;
		qcom,charger_lv_thr = <3400>;
		qcom,vbatt_full_thr = <4435>;
		qcom,vbatt_hv_thr = <4600>;

		qcom,vfloat_step_mv = <8>;
		qcom,cold_vfloat_over_sw_limit = <4500>;
		qcom,little_cold_vfloat_over_sw_limit = <4500>;
		qcom,cool_vfloat_over_sw_limit = <4500>;
		qcom,little_cool_vfloat_over_sw_limit = <4500>;
		qcom,normal_vfloat_over_sw_limit = <4480>;
		qcom,warm_vfloat_over_sw_limit = <4140>;
		qcom,non_standard_vfloat_over_sw_limit = <3990>;

		qcom,vbatt_power_off = <3300>;
		qcom,vbatt_soc_1 = <3410>;
		qcom,vooc_project = <21>;
		qcom,vbatt_num = <1>;
		qcom,voocphy_support = <2>;
		//qcom,chargerid_support;
		qcom,external_gauge;
		qcom,ffc_support;
		qcom,dual_ffc;
		qcom,sc6607_switch_ntc;
		oplus,aging_ffc_version = <1>;
		qcom,smart_charging_screenoff;
		qcom,vooc_show_ui_soc_decimal;
		qcom,ui_soc_decimal_speedmin = <20>;//2A
		qcom,ccdetect-gpio = <&tlmm 34 0x00>;
		oplus,boot_reset_adapter;
		qcom,check_batt_full_by_sw;
		qcom,chg_ctrl_by_lcd;
		qcom,chg_ctrl_by_camera;
		qcom,chg_ctrl_by_calling;
		qcom,support_ntc_01c_precision;
		qcom,sw_vfloat_over_protect_enable;

		qcom,normal_vterm_hw_inc = <18>;
		qcom,non_normal_vterm_hw_inc = <18>;
		qcom,usbtemp_batttemp_gap = <12>;

		qcom,ff1_normal_fastchg_ma = <1500>;
		qcom,ff1_warm_fastchg_ma = <1500>;

		qcom,ffc2_normal_fastchg_ma = <1400>;/*12C~35c*/
		qcom,ffc2_warm_fastchg_ma = <1000>;/*35C~40c*/
		qcom,ffc2_temp_low_decidegc = <120>;
		qcom,ffc2_temp_warm_decidegc = <350>;
		qcom,ffc2_temp_high_decidegc = <440>;

		qcom,ff1_exit_step_ma = <200>;
		qcom,ff1_warm_exit_step_ma = <200>;
		qcom,ffc2_exit_step_ma = <100>;
		qcom,ffc2_warm_exit_step_ma = <100>;

		qcom,ffc_normal_vfloat_sw_limit = <4545>;
		qcom,ffc_temp_normal_vfloat_mv = <4630>;
		qcom,ffc_normal_vfloat_over_sw_limit = <4630>;
		qcom,ffc_warm_vfloat_sw_limit = <4525>;

		qcom,ffc2_normal_vfloat_sw_limit = <4545>;
		qcom,ffc2_temp_normal_vfloat_mv = <4630>;
		qcom,ffc2_normal_vfloat_over_sw_limit = <4630>;
		qcom,ffc2_warm_vfloat_sw_limit = <4500>;

		qcom,default_iterm_ma = <292>;
		qcom,default_temp_normal_fastchg_current_ma = <2200>;
		qcom,default_normal_vfloat_sw_limit = <4420>;
		qcom,default_temp_normal_vfloat_mv = <4470>;
		qcom,default_normal_vfloat_over_sw_limit = <4480>;

		qcom,default_temp_little_cool_fastchg_current_ma = <2200>;
		qcom,default_little_cool_vfloat_sw_limit = <4440>;
		qcom,default_temp_little_cool_vfloat_mv = <4490>;
		qcom,default_little_cool_vfloat_over_sw_limit = <4500>;

		//for PD9V or QC9V
		qcom,vbatt_pdqc_to_5v_thr = <4500>;
		qcom,vbatt_pdqc_to_9v_thr = <4500>;

		//GPIO config:
		//qcom,chargerid_switch-gpio = <&tlmm 50 0x00>;
		qcom,dischg-gpio = <&pm6125_gpios 8 0x00>;
		qcom,usbtemp_chan_tmp;

		qcom,vooc-max-input-volt-support = <11000>;     //11V
		qcom,vooc-max-input-current-support = <4100>;   //4.1A
		qcom,use_vooc_charging_animation;
		qcom,qc_not_support = <1>;
		qcom,support_3p6_standard;
		qcom,usb_ntc_pullup = <100000>;
		qcom,mastercharger_psy_set;
		oplus,use_external_cclogic;
		oplus,not_support_usb_btb;
		qcom,support_usbtemp_protect_v2;
		qcom,usbtemp_batt_temp_low = <50>;
		qcom,usbtemp_batt_temp_high = <50>;
		qcom,usbtemp_ntc_temp_low = <57>;
		qcom,usbtemp_ntc_temp_high = <69>;
		qcom,usbtemp_temp_gap_low_with_batt_temp = <7>;
		qcom,usbtemp_temp_gap_high_with_batt_temp = <12>;
		qcom,usbtemp_temp_gap_low_without_batt_temp = <12>;
		qcom,usbtemp_temp_gap_high_without_batt_temp = <24>;
		qcom,usbtemp_rise_fast_temp_low = <3>;
		qcom,usbtemp_rise_fast_temp_high = <3>;
		qcom,usbtemp_rise_fast_temp_count_low = <30>;
		qcom,usbtemp_rise_fast_temp_count_high = <20>;

		qcom,usbtemp_cool_down_ntc_low = <54>;
		qcom,usbtemp_cool_down_ntc_high = <65>;
		qcom,usbtemp_cool_down_gap_low = <12>;
		qcom,usbtemp_cool_down_gap_high = <20>;
		qcom,usbtemp_cool_down_recover_ntc_low = <48>;
		qcom,usbtemp_cool_down_recover_ntc_high = <60>;
		qcom,usbtemp_cool_down_recover_gap_low = <6>;
		qcom,usbtemp_cool_down_recover_gap_high = <15>;

		qcom,gsm_call_on;
		qcom,smart_chg_soh_support;
		oplus,support_shipmode_in_chgic;
		oplus,smooth_switch_v2;
		oplus,reserve_chg_soc = <1>;
		oplus,reserve_dis_soc = <1>;

		qcom,usb_btb_support;
		//qcom,batt_btb_support;
		qcom,pa_thermal_support;
		//qcom,batt_thermal_support;
		qcom,bb_thermal_support;
		qcom,charger_thermal_support;
		qcom,quiet_thermal_support;
		qcom,flash_thermal_support;
		voocphy_support_display_vooc;
		oplus,support_hot_enter_kpoc;
		oplus,poweroff_high_batt_temp = <720>;
		oplus,poweroff_emergency_batt_temp = <770>;
		oplus,usbtemp_batt_temp_over_hot = <60>;
		oplus,usbtemp_temp_gap_with_batt_temp_in_over_hot = <15>;

		oplus,uart_tx-gpio = <&tlmm 12 0x00>;
		oplus,uart_rx-gpio = <&tlmm 13 0x00>;
	};
};

&qupv3_se4_2uart_pins{
	qupv3_se4_2uart_active: qupv3_se4_2uart_active {
		mux {
			pins = "gpio12", "gpio13";
			function = "qup4";
		};

		config {
			pins = "gpio12", "gpio13";
			drive-strength = <2>;
			bias-disable;
		};
	};

	qupv3_se4_2uart_sleep: qupv3_se4_2uart_sleep {
		mux {
			pins = "gpio12", "gpio13";
			function = "gpio";
		};

		config {
			pins = "gpio12", "gpio13";
			drive-strength = <2>;
			bias-pull-down;
			input-enable;
		};
	};
};
&usb0 {
	extcon = <&rpm>;
	#io-channel-cells = <1>;
	io-channels= <&discrete_charger PSY_IIO_USB_REAL_TYPE>;
	io-channel-names = "chg_type";
};
&qupv3_se4_2uart {
	pinctrl-names = "default", "sleep";
	pinctrl-0 = <&qupv3_se4_2uart_active>;
	pinctrl-1 = <&qupv3_se4_2uart_sleep>;
	status = "ok";
};
